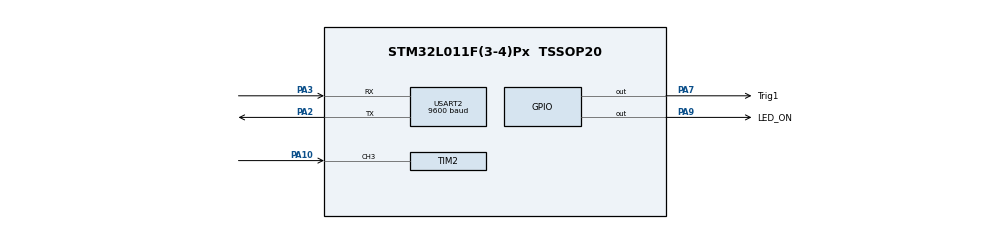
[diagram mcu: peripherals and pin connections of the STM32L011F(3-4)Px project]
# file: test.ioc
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Dma.Request0=USART2_RX
Dma.Request1=USART2_TX
Dma.USART2_RX.0.Direction=DMA_PERIPH_TO_MEMORY
Dma.USART2_RX.0.Instance=DMA1_Channel5
Dma.USART2_RX.0.MemDataAlignment=DMA_MDATAALIGN_BYTE
Dma.USART2_RX.0.MemInc=DMA_MINC_ENABLE
Dma.USART2_RX.0.Mode=DMA_NORMAL
Dma.USART2_RX.0.PeriphDataAlignment=DMA_PDATAALIGN_BYTE
Dma.USART2_RX.0.PeriphInc=DMA_PINC_DISABLE
Dma.USART2_RX.0.Priority=DMA_PRIORITY_LOW
Dma.USART2_TX.1.Direction=DMA_MEMORY_TO_PERIPH
Dma.USART2_TX.1.Instance=DMA1_Channel4
Dma.USART2_TX.1.MemDataAlignment=DMA_MDATAALIGN_BYTE
Dma.USART2_TX.1.MemInc=DMA_MINC_ENABLE
Dma.USART2_TX.1.Mode=DMA_NORMAL
Dma.USART2_TX.1.PeriphDataAlignment=DMA_PDATAALIGN_BYTE
Dma.USART2_TX.1.PeriphInc=DMA_PINC_DISABLE
Dma.USART2_TX.1.Priority=DMA_PRIORITY_LOW
Mcu.Family=STM32L0
Mcu.Name=STM32L011F(3-4)Px
Mcu.Package=TSSOP20
NVIC.DMA1_Channel4_5_IRQn=true\:0\:0\:false\:false\:true\:false\:true
NVIC.TIM2_IRQn=true\:0\:0\:false\:false\:true\:true\:true
NVIC.USART2_IRQn=true\:0\:0\:false\:false\:true\:true\:true
PA10.Signal=S_TIM2_CH3
PA13.Mode=Serial_Wire
PA13.Signal=SYS_SWDIO
PA14.Mode=Serial_Wire
PA14.Signal=SYS_SWCLK
PA2.Mode=Asynchronous
PA2.Signal=USART2_TX
PA3.Mode=Asynchronous
PA3.Signal=USART2_RX
PA7.GPIO_Label=Trig1
PA7.GPIO_ModeDefaultOutputPP=GPIO_MODE_OUTPUT_OD
PA7.GPIO_Speed=GPIO_SPEED_FREQ_VERY_HIGH
PA7.Signal=GPIO_Output
PA9.GPIO_Label=LED_ON
PA9.Signal=GPIO_Output
ProjectManager.HeapSize=0x100
ProjectManager.StackSize=0x200
ProjectManager.TargetToolchain=STM32CubeIDE
RCC.AHBFreq_Value=16000000
RCC.APB1Freq_Value=16000000
RCC.APB1TimFreq_Value=16000000
RCC.APB2Freq_Value=16000000
RCC.APB2TimFreq_Value=16000000
RCC.HCLKFreq_Value=16000000
RCC.HSE_VALUE=8000000
RCC.HSI16_VALUE=16000000
RCC.HSI_VALUE=16000000
RCC.LSE_VALUE=32768
RCC.MSI_VALUE=2097000
RCC.SYSCLKFreq_VALUE=16000000
RCC.SYSCLKSource=RCC_SYSCLKSOURCE_HSI
RCC.VCOOutputFreq_Value=48000000
SH.S_TIM2_CH3.0=TIM2_CH3,Input_Capture3_from_TI3
TIM2.Channel-Input_Capture3_from_TI3=TIM_CHANNEL_3
TIM2.ICPolarity_CH3=TIM_INPUTCHANNELPOLARITY_BOTHEDGE
USART2.BaudRate=9600
USART2.VirtualMode-Asynchronous=VM_ASYNC
VP_LPTIM1_VS_LPTIM_counterModeInternalClock.Mode=Counts__internal_clock_event_00
VP_TIM2_VS_ClockSourceINT.Mode=Internal
board=custom

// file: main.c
/* USER CODE BEGIN Header */
/**
  ******************************************************************************
  * @file           : main.c
  * @brief          : Main program body
  ******************************************************************************
  * @attention
  *
  * <h2><center>&copy; Copyright (c) 2021 STMicroelectronics.
  * All rights reserved.</center></h2>
  *
  * This software component is licensed by ST under BSD 3-Clause license,
  * the "License"; You may not use this file except in compliance with the
  * License. You may obtain a copy of the License at:
  *                        opensource.org/licenses/BSD-3-Clause
  *
  ******************************************************************************
  */
/* USER CODE END Header */
#include "main.h"
#include "dma.h"
#include "lptim.h"
#include "tim.h"
#include "usart.h"
#include "gpio.h"

void SystemClock_Config(void);

/* USER CODE BEGIN 0 */
TIM_HandleTypeDef htim2;
UART_HandleTypeDef huart2;

/* USER CODE END 0 */

int main(void)
{

  /* MCU Configuration--------------------------------------------------------*/

  /* Reset of all peripherals, Initializes the Flash interface and the Systick. */
  HAL_Init();

  /* Configure the system clock */
  SystemClock_Config();

  /* Initialize all configured peripherals */
  MX_GPIO_Init();
  MX_DMA_Init();
  MX_TIM2_Init();
  MX_LPTIM1_Init();
  MX_USART2_UART_Init();
  /* USER CODE BEGIN 2 */

  HAL_TIM_Base_Start_IT(&htim2);
  HAL_TIM_IC_Start_IT(&htim2, TIM_CHANNEL_3);

  start_calc();

  /* USER CODE END 2 */

  /* Infinite loop */
  while (1)
  {

  }
}

void SystemClock_Config(void)
{
  LL_FLASH_SetLatency(LL_FLASH_LATENCY_0);
  while(LL_FLASH_GetLatency()!= LL_FLASH_LATENCY_0)
  {
  }
  LL_PWR_SetRegulVoltageScaling(LL_PWR_REGU_VOLTAGE_SCALE1);
  LL_RCC_HSI_Enable();

   /* Wait till HSI is ready */
  while(LL_RCC_HSI_IsReady() != 1)
  {

  }
  LL_RCC_HSI_SetCalibTrimming(16);
  LL_RCC_SetAHBPrescaler(LL_RCC_SYSCLK_DIV_1);
  LL_RCC_SetAPB1Prescaler(LL_RCC_APB1_DIV_1);
  LL_RCC_SetAPB2Prescaler(LL_RCC_APB2_DIV_1);
  LL_RCC_SetSysClkSource(LL_RCC_SYS_CLKSOURCE_HSI);

   /* Wait till System clock is ready */
  while(LL_RCC_GetSysClkSource() != LL_RCC_SYS_CLKSOURCE_STATUS_HSI)
  {

  }
  LL_SetSystemCoreClock(16000000);

   /* Update the time base */
  if (HAL_InitTick (TICK_INT_PRIORITY) != HAL_OK)
  {
    Error_Handler();
  }
  LL_RCC_SetUSARTClockSource(LL_RCC_USART2_CLKSOURCE_PCLK1);
  LL_RCC_SetLPTIMClockSource(LL_RCC_LPTIM1_CLKSOURCE_PCLK1);
}

void Error_Handler(void)
{
  __disable_irq();
  while (1)
  {
  }
}

/************************ (C) COPYRIGHT STMicroelectronics *****END OF FILE****/
